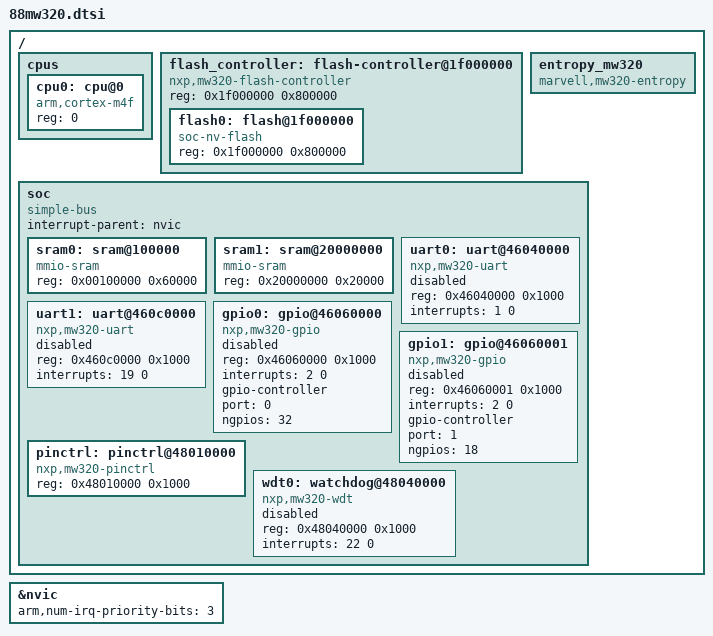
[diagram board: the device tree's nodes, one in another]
#include <arm/armv7-m.dtsi>

/ {
	#address-cells = <1>;
	#size-cells = <1>;

	cpus {
		#address-cells = <1>;
		#size-cells = <0>;

		cpu0: cpu@0 {
			device_type = "cpu";
			compatible = "arm,cortex-m4f";
			reg = <0>;
		};
	};

	flash_controller: flash-controller@1f000000 {
		compatible = "nxp,mw320-flash-controller";
		reg = <0x1f000000 0x800000>;
		#address-cells = <1>;
		#size-cells = <1>;

		flash0: flash@1f000000 {
			compatible = "soc-nv-flash";
			reg = <0x1f000000 0x800000>;
		};
	};

	entropy_mw320: entropy_mw320 {
		compatible = "marvell,mw320-entropy";
		status = "okay";
	};

	soc {
		#address-cells = <1>;
		#size-cells = <1>;
		compatible = "simple-bus";
		interrupt-parent = <&nvic>;
		ranges;

		sram0: sram@100000 {
			compatible = "mmio-sram";
			reg = <0x00100000 0x60000>;
		};

		sram1: sram@20000000 {
			compatible = "mmio-sram";
			reg = <0x20000000 0x20000>;
		};

		uart0: uart@46040000 {
			compatible = "nxp,mw320-uart";
			reg = <0x46040000 0x1000>;
			interrupts = <1 0>;
			status = "disabled";
		};

		uart1: uart@460c0000 {
			compatible = "nxp,mw320-uart";
			reg = <0x460c0000 0x1000>;
			interrupts = <19 0>;
			status = "disabled";
		};

		gpio0: gpio@46060000 {
			compatible = "nxp,mw320-gpio";
			reg = <0x46060000 0x1000>;
			interrupts = <2 0>;
			gpio-controller;
			#gpio-cells = <2>;
			port = <0>;
			ngpios = <32>;
			status = "disabled";
		};

		/* WORKAROUND: gpio0 and gpio1 share the same physical base address (0x46060000).
		 * To satisfy dtc's unique_unit_address and simple_bus_reg checks, we assign
		 * gpio1 a dummy unit address and reg of 0x46060001. The gpio_mw320 driver
		 * has been patched to ignore this and use the hardcoded GPIO_BASE. */
		gpio1: gpio@46060001 {
			compatible = "nxp,mw320-gpio";
			reg = <0x46060001 0x1000>;
			interrupts = <2 0>;
			gpio-controller;
			#gpio-cells = <2>;
			port = <1>;
			ngpios = <18>;
			status = "disabled";
		};

		pinctrl: pinctrl@48010000 {
			compatible = "nxp,mw320-pinctrl";
			reg = <0x48010000 0x1000>;
		};

		wdt0: watchdog@48040000 {
			compatible = "nxp,mw320-wdt";
			reg = <0x48040000 0x1000>;
			interrupts = <22 0>;
			status = "disabled";
		};
	};
};

&nvic {
	arm,num-irq-priority-bits = <3>;
};
